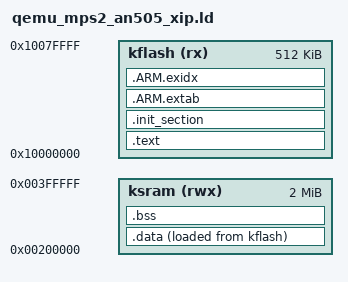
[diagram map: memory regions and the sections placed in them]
/****************************************************************************
 *
 * Copyright 2026 Samsung Electronics All Rights Reserved.
 *
 * Licensed under the Apache License, Version 2.0 (the "License");
 * you may not use this file except in compliance with the License.
 * You may obtain a copy of the License at
 *
 * http://www.apache.org/licenses/LICENSE-2.0
 *
 * Unless required by applicable law or agreed to in writing, software
 * distributed under the License is distributed on an "AS IS" BASIS,
 * WITHOUT WARRANTIES OR CONDITIONS OF ANY KIND, either express or implied.
 * See the License for the specific language governing permissions and
 * limitations under the License.
 *
 ****************************************************************************/

MEMORY
{
    kflash (rx)  : ORIGIN = 0x10000000, LENGTH = 512K
    /* Keep kernel RAM in the secure SSRAM window. QEMU raises AUVIOL when
     * the first thread exception frame is unstacked from the generic
     * mps.ram region or from the MPC-routed aliases.
     */
    ksram  (rwx) : ORIGIN = 0x00200000, LENGTH = 2M
}

OUTPUT_ARCH(arm)
EXTERN(_vectors)
ENTRY(__start)

SECTIONS
{
    .text : {
        _stext_flash = ABSOLUTE(.);
        __vector_table = ABSOLUTE(.);
        KEEP(*(.vectors))
        *(.text .text.*)
        *(.fixup)
        *(.gnu.warning)
        *(.rodata .rodata.*)
        *(.gnu.linkonce.t.*)
        *(.gnu.linkonce.r.*)
        *(.glue_7)
        *(.glue_7t)
        *(.got)
        *(.gcc_except_table)
        _etext_flash = ABSOLUTE(.);
    } > kflash

    .init_section : {
        _sinit = ABSOLUTE(.);
        *(.init_array .init_array.*)
        _einit = ABSOLUTE(.);
    } > kflash

    .ARM.extab : {
        *(.ARM.extab*)
    } > kflash

    __exidx_start = ABSOLUTE(.);
    .ARM.exidx : {
        *(.ARM.exidx*)
    } > kflash
    __exidx_end = ABSOLUTE(.);

    _eronly = ABSOLUTE(.);
    _stext_ram = ABSOLUTE(.);
    _etext_ram = ABSOLUTE(.);

    .data : {
        _sdata = ABSOLUTE(.);
        *(.data .data.*)
        *(.gnu.linkonce.d.*)
        CONSTRUCTORS
        _edata = ABSOLUTE(.);
    } > ksram AT > kflash

    .bss : {
        _sbss = ABSOLUTE(.);
        *(.bss .bss.*)
        *(.gnu.linkonce.b.*)
        *(COMMON)
        . = ALIGN(8);
        _ebss = ABSOLUTE(.);
        _sidle_stack = ABSOLUTE(.);
        . = . + CONFIG_IDLETHREAD_STACKSIZE;
        . = ALIGN(8);
        _sint_heap = ABSOLUTE(.);
    } > ksram

    .stab 0 : { *(.stab) }
    .stabstr 0 : { *(.stabstr) }
    .stab.excl 0 : { *(.stab.excl) }
    .stab.exclstr 0 : { *(.stab.exclstr) }
    .stab.index 0 : { *(.stab.index) }
    .stab.indexstr 0 : { *(.stab.indexstr) }
    .comment 0 : { *(.comment) }
    .debug_abbrev 0 : { *(.debug_abbrev) }
    .debug_info 0 : { *(.debug_info) }
    .debug_line 0 : { *(.debug_line) }
    .debug_pubnames 0 : { *(.debug_pubnames) }
    .debug_aranges 0 : { *(.debug_aranges) }
}
